# STM32U5Fx register map
File version: 1.0
CPU: CM33 r0p1, little endian, MPU, FPU, 4 interrupt priority bits
Registers are 32-bit, read-write, reset 0x0 unless marked. A register's access mark holds for its fields unless they carry their own. Offsets are from the block's base; [hi:lo] are bit positions; lines under a group give offsets from that group; {n}, {i} and the like mark numbered series; 'fields as' and 'values as' point back to an identical list.

## TIM6 — General-purpose-timers
Base 0x40001000
Same registers: TIM7 0x40001400, SEC_TIM6 0x50001000, SEC_TIM7 0x50001400
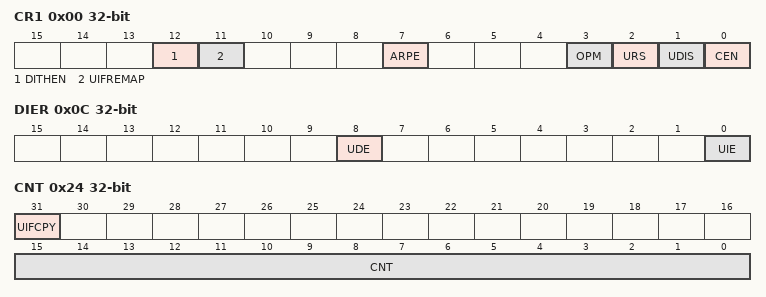
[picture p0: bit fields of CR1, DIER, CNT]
0x00 CR1 — control register 1
  [12] DITHEN — Dithering Enable
  [11] UIFREMAP — UIF status bit remapping
  [7] ARPE — Auto-reload preload enable
  [3] OPM — One-pulse mode
  [2] URS — Update request source
  [1] UDIS — Update disable
  [0] CEN — Counter enable
0x04 CR2 — control register 2
  [6:4] MMS — Master mode selection
0x0C DIER — DMA/Interrupt enable register
  [8] UDE, [0] UIE
0x10 SR — status register
  [0] UIF
0x14 EGR wo — event generation register
  [0] UG
0x24 CNT — counter
  [31] UIFCPY, [15:0] CNT
0x28 PSC — prescaler
  [15:0] PSC
0x2C ARR reset 0xFFFF — auto-reload register
  [19:0] ARR

## TSC — Touch sensing controller
Base 0x40024000
Same registers: SEC_TSC 0x50024000
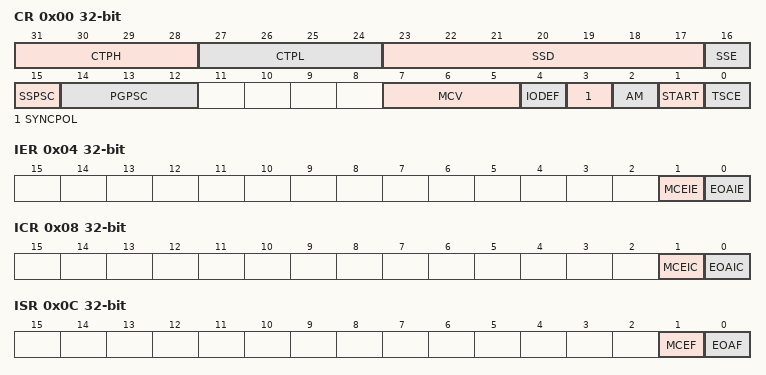
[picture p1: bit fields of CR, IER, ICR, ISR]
0x00 CR — control register
  [31:28] CTPH — Charge transfer pulse high
  [27:24] CTPL — Charge transfer pulse low
  [23:17] SSD — Spread spectrum deviation
  [16] SSE — Spread spectrum enable
  [15] SSPSC — Spread spectrum prescaler
  [14:12] PGPSC — pulse generator prescaler
  [7:5] MCV — Max count value
  [4] IODEF — I/O Default mode
  [3] SYNCPOL — Synchronization pin polarity
  [2] AM — Acquisition mode
  [1] START — Start a new acquisition
  [0] TSCE — Touch sensing controller enable
0x04 IER — interrupt enable register
  [1] MCEIE — Max count error interrupt enable
  [0] EOAIE — End of acquisition interrupt enable
0x08 ICR — interrupt clear register
  [1] MCEIC — Max count error interrupt clear
  [0] EOAIC — End of acquisition interrupt clear
0x0C ISR ro — interrupt status register
  [1] MCEF — Max count error flag
  [0] EOAF — End of acquisition flag
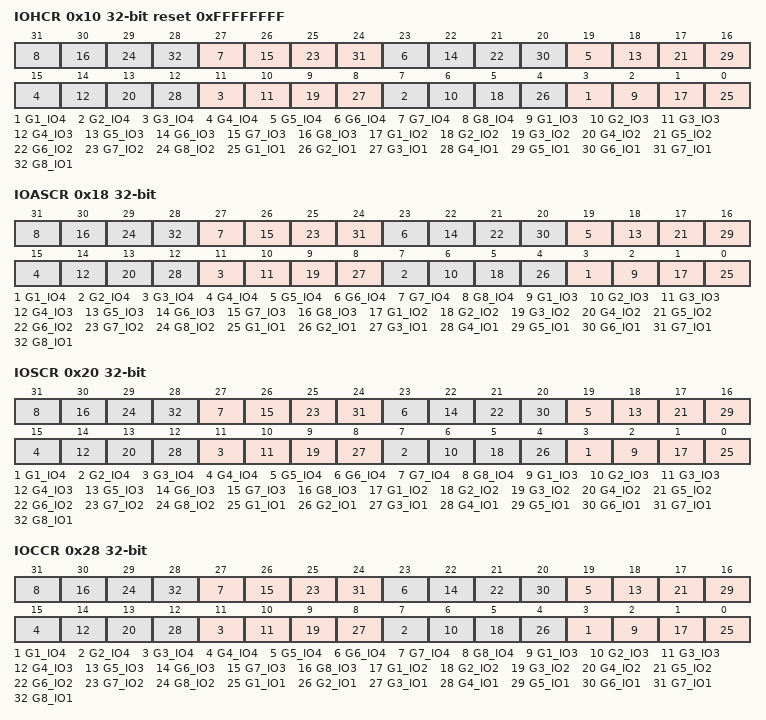
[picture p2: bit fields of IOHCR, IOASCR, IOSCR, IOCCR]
0x10 IOHCR reset 0xFFFFFFFF — I/O hysteresis control register
  [4n-1] G{n}_IO4 (n=1..8), [4n-2] G{n}_IO3 (n=1..8), [4n-3] G{n}_IO2 (n=1..8), [4n-4] G{n}_IO1 (n=1..8)
0x18 IOASCR — I/O analog switch control register
  fields as IOHCR
0x20 IOSCR — I/O sampling control register
  fields as IOHCR
0x28 IOCCR — I/O channel control register
  fields as IOHCR
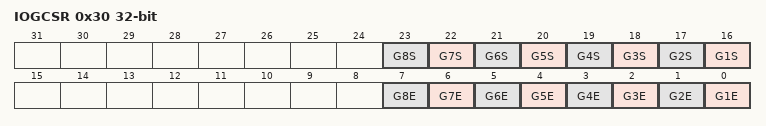
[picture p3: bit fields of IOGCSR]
0x30 IOGCSR access per field — I/O group control status register
  [n+15] G{n}S ro (n=1..8) — Analog I/O group x status
  [n-1] G{n}E rw (n=1..8) — Analog I/O group x enable
{0x30+4i} IOG{i}CR ro (i=1..8) — I/O group x counter register
  [13:0] CNT — Counter value

## UCPD1 — USB Power Delivery interface
Base 0x4000DC00
Same registers: SEC_UCPD1 0x5000DC00
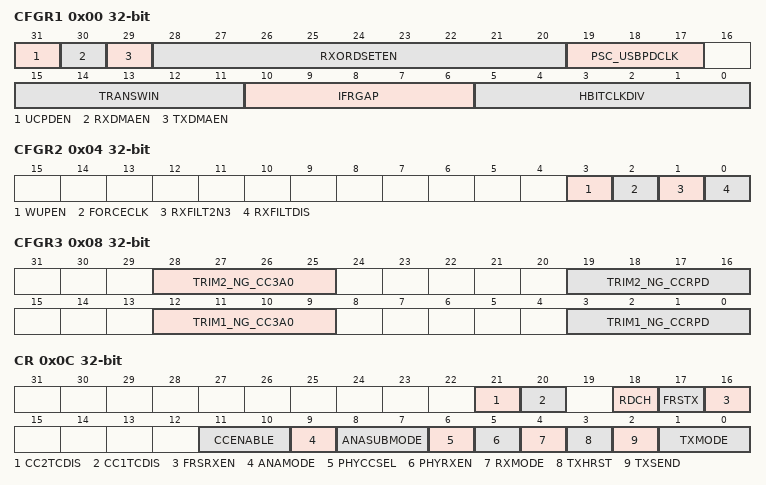
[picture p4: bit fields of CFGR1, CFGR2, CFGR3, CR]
0x00 CFGR1 — UCPD configuration register 1
  [31] UCPDEN, [30] RXDMAEN, [29] TXDMAEN, [28:20] RXORDSETEN, [19:17] PSC_USBPDCLK, [15:11] TRANSWIN, [10:6] IFRGAP, [5:0] HBITCLKDIV
0x04 CFGR2 — UCPD configuration register 2
  [3] WUPEN, [2] FORCECLK, [1] RXFILT2N3, [0] RXFILTDIS
0x08 CFGR3 — UCPD configuration register 3
  [28:25] TRIM2_NG_CC3A0, [19:16] TRIM2_NG_CCRPD, [12:9] TRIM1_NG_CC3A0, [3:0] TRIM1_NG_CCRPD
0x0C CR — UCPD control register
  [21] CC2TCDIS, [20] CC1TCDIS, [18] RDCH, [17] FRSTX, [16] FRSRXEN, [11:10] CCENABLE, [9] ANAMODE, [8:7] ANASUBMODE, [6] PHYCCSEL, [5] PHYRXEN, [4] RXMODE, [3] TXHRST, [2] TXSEND, [1:0] TXMODE
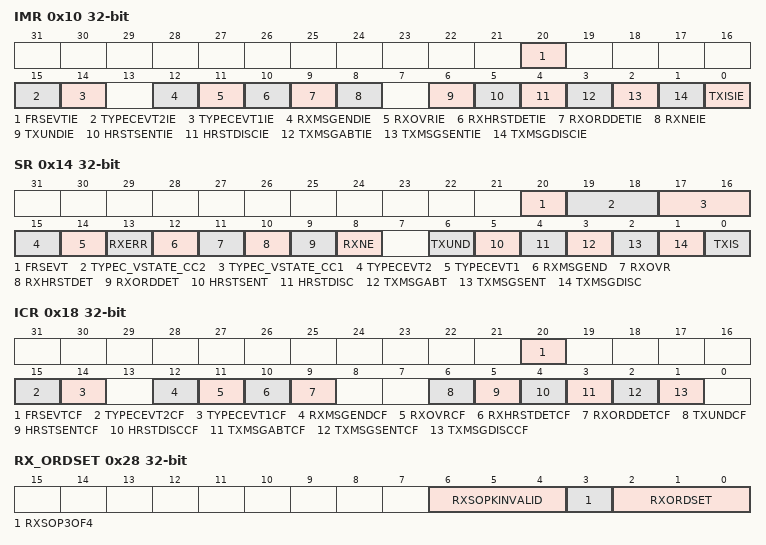
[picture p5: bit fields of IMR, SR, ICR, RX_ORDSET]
0x10 IMR — UCPD Interrupt Mask Register
  [20] FRSEVTIE, [15] TYPECEVT2IE, [14] TYPECEVT1IE, [12] RXMSGENDIE, [11] RXOVRIE, [10] RXHRSTDETIE, [9] RXORDDETIE, [8] RXNEIE, [6] TXUNDIE, [5] HRSTSENTIE, [4] HRSTDISCIE, [3] TXMSGABTIE, [2] TXMSGSENTIE, [1] TXMSGDISCIE, [0] TXISIE
0x14 SR ro — UCPD Status Register
  [20] FRSEVT, [19:18] TYPEC_VSTATE_CC2, [17:16] TYPEC_VSTATE_CC1, [15] TYPECEVT2, [14] TYPECEVT1, [13] RXERR, [12] RXMSGEND, [11] RXOVR, [10] RXHRSTDET, [9] RXORDDET, [8] RXNE, [6] TXUND, [5] HRSTSENT, [4] HRSTDISC, [3] TXMSGABT, [2] TXMSGSENT, [1] TXMSGDISC, [0] TXIS
0x18 ICR wo — UCPD Interrupt Clear Register
  [20] FRSEVTCF, [15] TYPECEVT2CF, [14] TYPECEVT1CF, [12] RXMSGENDCF, [11] RXOVRCF, [10] RXHRSTDETCF, [9] RXORDDETCF, [6] TXUNDCF, [5] HRSTSENTCF, [4] HRSTDISCCF, [3] TXMSGABTCF, [2] TXMSGSENTCF, [1] TXMSGDISCCF
0x1C TX_ORDSET — UCPD Tx Ordered Set Type Register
  [19:0] TXORDSET
0x20 TX_PAYSZ — UCPD Tx payload size Register
  [9:0] TXPAYSZ
0x24 TXDR — UCPD Tx Data Register
  [7:0] TXDATA
0x28 RX_ORDSET ro — UCPD Rx Ordered Set Register
  [6:4] RXSOPKINVALID, [3] RXSOP3OF4, [2:0] RXORDSET
0x2C RX_PAYSZ ro — UCPD Rx payload size Register
  [9:0] RXPAYSZ
0x30 RXDR ro — UCPD Receive Data Register
  [7:0] RXDATA
0x34 RX_ORDEXT1 — UCPD Rx Ordered Set Extension Register 1
  [19:0] RXSOPX1
0x38 RX_ORDEXT2 — UCPD Rx Ordered Set Extension Register 2
  [19:0] RXSOPX2

## VREFBUF — Voltage reference buffer
Base 0x46007400
Same registers: SEC_VREFBUF 0x56007400
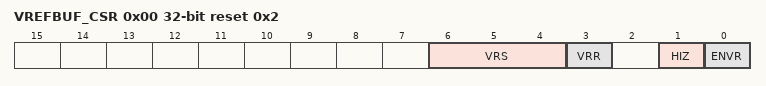
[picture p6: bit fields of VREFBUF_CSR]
0x00 VREFBUF_CSR access per field reset 0x2 — VREFBUF control and status register
  [6:4] VRS rw, [3] VRR ro, [1] HIZ rw, [0] ENVR rw
0x04 VREFBUF_CCR — VREFBUF calibration control register
  [5:0] TRIM

## WWDG — System window watchdog
Base 0x40002C00
Same registers: SEC_WWDG 0x50002C00
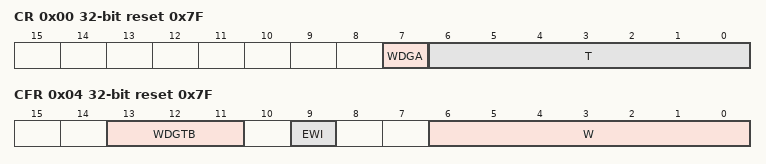
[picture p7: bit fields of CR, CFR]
0x00 CR reset 0x7F — Control register
  [7] WDGA — Activation bit
  [6:0] T — 7-bit counter (MSB to LSB)
0x04 CFR reset 0x7F — Configuration register
  [13:11] WDGTB — Timer base
  [9] EWI — Early wakeup interrupt
  [6:0] W — 7-bit window value
0x08 SR — Status register
  [0] EWIF — Early wakeup interrupt flag

## DCB — Debug Control Block
Base 0xE000EE08
0x00 DSCSR — Debug Security Control and Status Register
  [16] CDS — Current domain Secure
